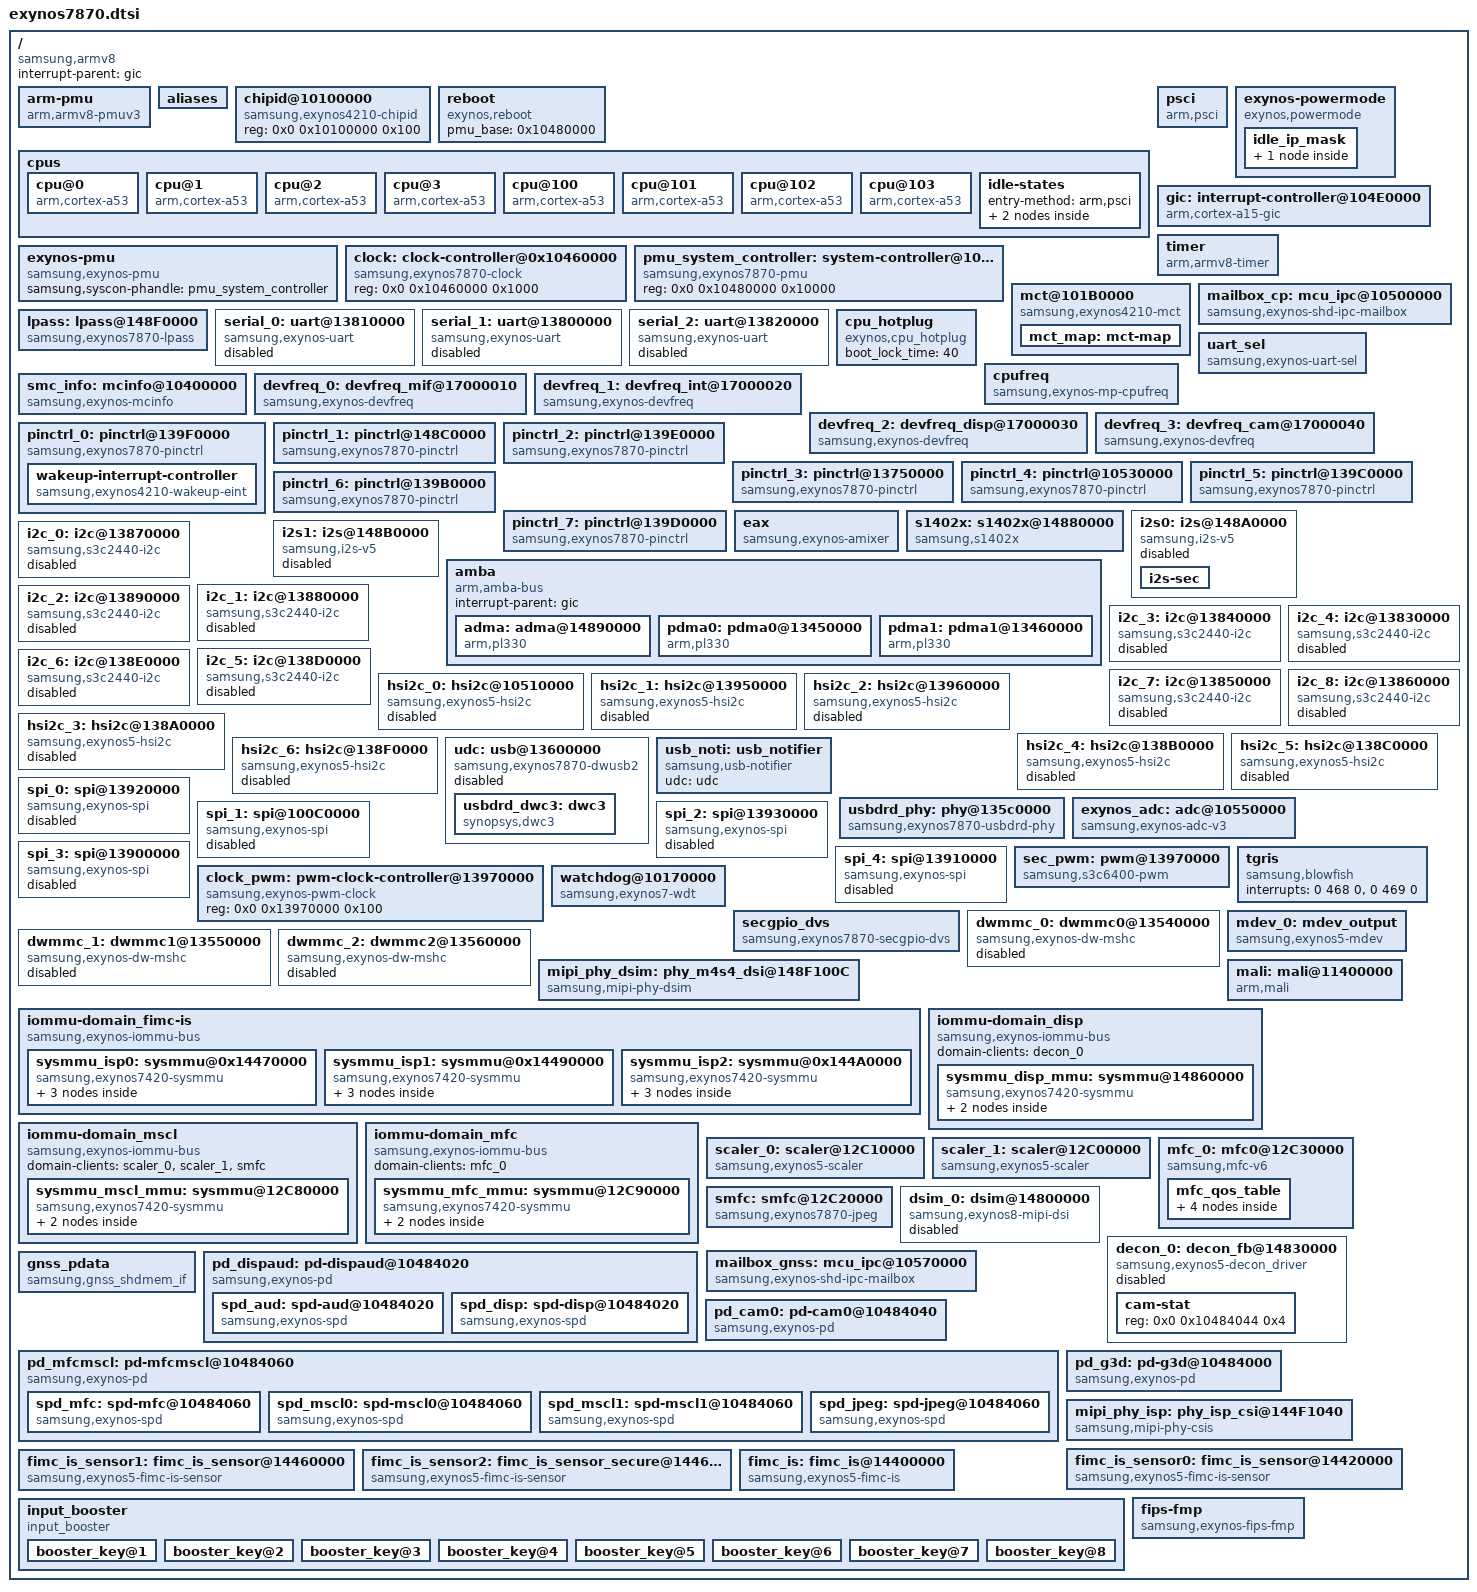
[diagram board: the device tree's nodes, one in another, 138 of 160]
/*
 * SAMSUNG EXYNOS7870 SoC device tree source
 *
 * Copyright (c) 2015 Samsung Electronics Co., Ltd.
 *		http://www.samsung.com
 *
 * SAMSUNG EXYNOS7870 SoC device nodes are listed in this file.
 * EXYNOS7870 based board files can include this file and provide
 * values for board specfic bindings.
 *
 * This program is free software; you can redistribute it and/or modify
 * it under the terms of the GNU General Public License version 2 as
 * published by the Free Software Foundation.
 */


#include <dt-bindings/clock/exynos7870.h>
#include <dt-bindings/sysmmu/sysmmu.h>
#include <dt-bindings/thermal/thermal.h>

#include "exynos7870-pinctrl.dtsi"
#include "exynos7870-busmon.dtsi"

/ {
	compatible = "samsung,armv8", "samsung,exynos7870";
	interrupt-parent = <&gic>;
	#address-cells = <2>;
	#size-cells = <1>;

	arm-pmu {
		compatible = "arm,armv8-pmuv3";
		interrupts = <0 34 4>,
			     <0 35 4>,
			     <0 36 4>,
			     <0 37 4>,
			     <0 50 4>,
			     <0 51 4>,
			     <0 52 4>,
			     <0 53 4>;
	};

	aliases {
		pinctrl0 = &pinctrl_0;
		pinctrl1 = &pinctrl_1;
		pinctrl2 = &pinctrl_2;
		pinctrl3 = &pinctrl_3;
		pinctrl4 = &pinctrl_4;
		pinctrl5 = &pinctrl_5;
		pinctrl6 = &pinctrl_6;
		pinctrl7 = &pinctrl_7;
		uart0 = &serial_0;
		uart1 = &serial_1;
		uart2 = &serial_2;
		hsi2c0 = &hsi2c_0;
		hsi2c1 = &hsi2c_1;
		hsi2c2 = &hsi2c_2;
		hsi2c3 = &hsi2c_3;
		hsi2c4 = &hsi2c_4;
		hsi2c5 = &hsi2c_5;
		hsi2c6 = &hsi2c_6;
		spi0 = &spi_0;
		spi1 = &spi_1;
		spi2 = &spi_2;
		spi3 = &spi_3;
		spi4 = &spi_4;
		mshc0 = &dwmmc_0;
//+++ MRVL_LOCAL
		mshc1 = &dwmmc_1;
//--- MRVL_LOCAL
		mshc2 = &dwmmc_2;
		decon0 = &decon_0;
		dsim0 = &dsim_0;
		scaler0 = &scaler_0;
		scaler1 = &scaler_1;
		mfc0 = &mfc_0;
		tmuctrl0 = &tmuctrl_0;
		tmuctrl1 = &tmuctrl_1;
		tmuctrl2 = &tmuctrl_2;
		ni2c0 = &i2c_0;
		ni2c1 = &i2c_1;
		ni2c2 = &i2c_2;
		ni2c3 = &i2c_3;
		ni2c4 = &i2c_4;
		ni2c5 = &i2c_5;
		ni2c6 = &i2c_6;
		ni2c7 = &i2c_7;
		ni2c8 = &i2c_8;
	};

	chipid@10100000 {
		compatible = "samsung,exynos4210-chipid";
		reg = <0x0 0x10100000 0x100>;
	};

	reboot {
		compatible = "exynos,reboot";
		pmu_base = <0x10480000>;
	};

	cpus {
		#address-cells = <2>;
		#size-cells = <0>;

		cpu@0 {
			device_type = "cpu";
			compatible = "arm,cortex-a53", "arm,armv8";
			reg = <0x0 0x0>;
			enable-method = "psci";
			cpu-idle-states = <&CPU_SLEEP_BOOT>;
		};
		cpu@1 {
			device_type = "cpu";
			compatible = "arm,cortex-a53", "arm,armv8";
			reg = <0x0 0x1>;
			enable-method = "psci";
			cpu-idle-states = <&CPU_SLEEP_BOOT>;
		};
		cpu@2 {
			device_type = "cpu";
			compatible = "arm,cortex-a53", "arm,armv8";
			reg = <0x0 0x2>;
			enable-method = "psci";
			cpu-idle-states = <&CPU_SLEEP_BOOT>;
		};
		cpu@3 {
			device_type = "cpu";
			compatible = "arm,cortex-a53", "arm,armv8";
			reg = <0x0 0x3>;
			enable-method = "psci";
			cpu-idle-states = <&CPU_SLEEP_BOOT>;
		};
		cpu@100 {
			device_type = "cpu";
			compatible = "arm,cortex-a53", "arm,armv8";
			reg = <0x0 0x100>;
			enable-method = "psci";
			cpu-idle-states = <&CPU_SLEEP_NONBOOT>;
		};
		cpu@101 {
			device_type = "cpu";
			compatible = "arm,cortex-a53", "arm,armv8";
			reg = <0x0 0x101>;
			enable-method = "psci";
			cpu-idle-states = <&CPU_SLEEP_NONBOOT>;
		};
		cpu@102 {
			device_type = "cpu";
			compatible = "arm,cortex-a53", "arm,armv8";
			reg = <0x0 0x102>;
			enable-method = "psci";
			cpu-idle-states = <&CPU_SLEEP_NONBOOT>;
		};
		cpu@103 {
			device_type = "cpu";
			compatible = "arm,cortex-a53", "arm,armv8";
			reg = <0x0 0x103>;
			enable-method = "psci";
			cpu-idle-states = <&CPU_SLEEP_NONBOOT>;
		};
		idle-states {
			entry-method = "arm,psci";

			CPU_SLEEP_BOOT: cpu-sleep-boot {
				desc = "boot cluster cpu sleep";
				compatible = "exynos,idle-state";
				arm,psci-suspend-param = <0x0010000>;
				entry-latency-us = <35>;
				exit-latency-us = <90>;
				min-residency-us = <750>;
				status = "okay";
			};

			CPU_SLEEP_NONBOOT: cpu-sleep-nonboot {
				desc = "non-boot cluster cpu sleep";
				compatible = "exynos,idle-state";
				arm,psci-suspend-param = <0x0010000>;
				entry-latency-us = <35>;
				exit-latency-us = <90>;
				min-residency-us = <750>;
				status = "okay";
			};
		};
	};

	exynos-pmu {
		compatible = "samsung,exynos-pmu";
		samsung,syscon-phandle = <&pmu_system_controller>;
	};

	psci {
                compatible = "arm,psci";
                method = "smc";
                cpu_suspend = <0xC4000001>;
                cpu_off = <0x84000002>;
                cpu_on = <0xC4000003>;
        };

	exynos-powermode {
		compatible = "exynos,powermode";

		/*	        sicd		aftr	stop	lpd	sleep	*/
		wakeup_mask =  <0x40000000>,	<0x0>,	<0x0>,	<0x0>,	<0x50006E1E>;
		wakeup_mask2 = <0x0>,		<0x0>,	<0x0>,	<0x0>,	<0xFFFF00FF>;
		wakeup_mask3 = <0x0>,		<0x0>,	<0x0>,	<0x0>,	<0xFFFF00FF>;

		cpd_residency = <3000>;
		sicd_residency = <3000>;

		sicd_enabled = <1>;

		idle-ip = "13970000.pwm",		/* idle ip index : 0 */
			  "10550000.adc",		/* idle ip index : 1 */

			  "10510000.hsi2c",		/* idle ip index : 2 */
			  "13950000.hsi2c",		/* idle ip index : 3 */
			  "13960000.hsi2c",		/* idle ip index : 4 */
			  "138a0000.hsi2c",		/* idle ip index : 5 */
			  "138b0000.hsi2c",		/* idle ip index : 6 */
			  "138c0000.hsi2c",		/* idle ip index : 7 */
			  "138f0000.hsi2c",		/* idle ip index : 8 */

			  "13870000.i2c",		/* idle ip index : 9 */
			  "13880000.i2c",		/* idle ip index : 10 */
			  "13890000.i2c",		/* idle ip index : 11 */
			  "13840000.i2c",		/* idle ip index : 12 */
			  "13830000.i2c",		/* idle ip index : 13 */
			  "138d0000.i2c",		/* idle ip index : 14 */
			  "138e0000.i2c",		/* idle ip index : 15 */
			  "13850000.i2c",		/* idle ip index : 16 */
			  "13860000.i2c",		/* idle ip index : 17 */

			  "13540000.dwmmc0",		/* idle ip index : 18 */
			  "13550000.dwmmc1",		/* idle ip index : 19 */
			  "13560000.dwmmc2",		/* idle ip index : 20 */

			  "13600000.usb",		/* idle ip index : 21 */

			  "100c0000.spi",		/* idle ip index : 22 */
			  "13900000.spi",		/* idle ip index : 23 */
			  "13910000.spi",		/* idle ip index : 24 */
			  "13920000.spi",		/* idle ip index : 25 */
			  "13930000.spi",		/* idle ip index : 26 */

			  "10500000.mailbox-cp",	/* idle ip index : 27 */
			  "10570000.mailbox-gnss",	/* idle ip index : 28 */

			  "14830000.decon_fb",		/* idle ip index : 29 */
			  "pd-g3d",			/* idle ip index : 30 */
			  "pd-cam0",			/* idle ip index : 31 */
			  "pd-mfcmscl",			/* idle ip index : 32 */
			  "148f0000.lpass",             /* idle ip index : 33 */
			  "bluetooth";			/* idle ip index : 34 */
		idle_ip_mask {
			sicd: SYS_SICD {
				mode-index = <0>;
				ref-idle-ip = <0>,  <1>,  <2>,  <3>,  <4>,  <5>,  <6>,  <7>,  <8>,  <9>,
					     <10>, <11>, <12>, <13>, <14>, <15>, <16>, <17>, <18>, <19>,
					     <20>, <21>, <22>, <23>, <24>, <25>, <26>, <27>, <28>, <29>,
					     <30>, <31>, <32>, <33>, <34>;
			};
		};
	};

	gic:interrupt-controller@104E0000 {
		compatible = "arm,cortex-a15-gic", "arm,cortex-a9-gic";
		#interrupt-cells = <3>;
		#address-cells = <0>;
		interrupt-controller;
		reg =	<0x0 0x104E1000 0x1000>,
			<0x0 0x104E2000 0x1000>,
			<0x0 0x104E4000 0x2000>,
			<0x0 0x104E6000 0x2000>;
		interrupts = <1 9 0xf04>;
	};

	timer {
	        compatible = "arm,armv8-timer";
	        interrupts = <1 13 0xff01>,
	                     <1 14 0xff01>,
	                     <1 11 0xff01>,
	                     <1 10 0xff01>;
	        clock-frequency = <26000000>;
		use-clocksource-only;
	};

	clock: clock-controller@0x10460000 {
		compatible = "samsung,exynos7870-clock";
		reg = <0x0 0x10460000 0x1000>;
		#clock-cells = <1>;
	};

	pmu_system_controller: system-controller@10480000 {
		compatible = "samsung,exynos7870-pmu", "syscon";
		reg = <0x0 0x10480000 0x10000>;
	};

	mct@101B0000 {
		compatible = "samsung,exynos4210-mct";
		reg = <0x0 0x101B0000 0x800>;
		interrupt-controller;
		#interrupt-cells = <1>;
		interrupt-parent = <&mct_map>;
		interrupts =	<0>, <1>, <2>, <3>,
				<4>, <5>, <6>, <7>,
				<8>, <9>, <10>, <11>;
		clocks = <&clock 1>, <&clock 102>;
		clock-names = "fin_pll", "mct";
		use-clockevent-only;

		mct_map: mct-map {
			#interrupt-cells = <1>;
			#address-cells = <0>;
			#size-cells = <0>;
			interrupt-map = <0 &gic 0 102 0>,
					<1 &gic 0 103 0>,
					<2 &gic 0 104 0>,
					<3 &gic 0 105 0>,
					<4 &gic 0 106 0>,
					<5 &gic 0 107 0>,
					<6 &gic 0 108 0>,
					<7 &gic 0 109 0>,
					<8 &gic 0 110 0>,
					<9 &gic 0 111 0>,
					<10 &gic 0 112 0>,
					<11 &gic 0 113 0>;
		};
	};

	mailbox_cp: mcu_ipc@10500000 {
		compatible = "samsung,exynos7580-mailbox";

		reg = <0 0x10500000 0x17C>;
		interrupts = <0 369 0 >;

		mcu,id = <0>;
		mcu,name = "mcu_ipc";
		mcu,irq_affinity_mask = <3>;
	};

	lpass: lpass@148F0000 {
		compatible = "samsung,exynos7870-lpass";
		reg = <0x0 0x148F0000 0x1040>;
		clocks = <&clock 461>,		/* aud_pll */
			<&clock 413>,		/* dispaud_mi2s_aud */
			<&clock 462>,		/* d1_mi2s */
			<&clock 410>; 		/* dispaud_decon */

		clock-names = "fout_aud_pll", "dout_sclk_mi2s",
				"aclk_aud", "dispaud_decon";

		samsung,syscon-phandle = <&pmu_system_controller>;
		samsung,power-domain = <&spd_aud>;
		status = "okay";
	};

	/* UART_BTWIFIFM */
	serial_0: uart@13810000 {
		compatible = "samsung,exynos-uart";
		samsung,separate-uart-clk;
		reg = <0x0 0x13810000 0x100>;
		samsung,fifo-size = <256>;
		interrupts = <0 422 0>;
		pinctrl-names = "default";
		pinctrl-0 = <&uart0_bus>;
		clocks = <&clock 171>, <&clock 621>, <&clock 621>;
		clock-names = "gate_pclk0", "gate_uart0", "sclk_uart0";
		status = "disabled";
	};

	/* UART_SENSOR */
	serial_1: uart@13800000 {
		compatible = "samsung,exynos-uart";
		samsung,separate-uart-clk;
		reg = <0x0 0x13800000 0x100>;
		samsung,fifo-size = <16>;
		interrupts = <0 421 0>;
		pinctrl-names = "default";
		pinctrl-0 = <&uart1_bus>;
		clocks = <&clock 172>, <&clock 620>, <&clock 620>;
		clock-names = "gate_pclk1", "gate_uart1", "sclk_uart1";
		status = "disabled";
	};

	/* UART_DEBUG */
	serial_2: uart@13820000 {
		compatible = "samsung,exynos-uart";
		samsung,separate-uart-clk;
		reg = <0x0 0x13820000 0x100>;
		samsung,fifo-size = <256>;
		interrupts = <0 423 0>;
		pinctrl-names = "default", "uart_sleep";
		pinctrl-0 = <&uart2_bus>;
		pinctrl-1 = <&uart2_sleep>;
		clocks = <&clock 170>, <&clock 622>, <&clock 622>;
		clock-names = "gate_pclk2", "gate_uart2", "sclk_uart2";
		status = "disabled";
	};

	/* UART SWITCH FOR CP */
	uart_sel {
		compatible = "samsung,exynos-uart-sel";

		mbx_ap2cp_uart_noti = <30>;
		int_ap2cp_uart_noti = <15>;
	};

	cpu_hotplug {
		compatible = "exynos,cpu_hotplug";
		boot_lock_time = <40>;
	};

	cpufreq {
		compatible = "samsung,exynos-mp-cpufreq";

		/* For CPUFREQ table */
		/* CL0 */
		cl0_idx_num = <17>;
		cl0_max_support_idx = <2>;
		cl0_min_support_idx = <14>;
		cl0_boot_max_qos = <1482000>;
		cl0_boot_min_qos = <1482000>;
		cl0_boot_lock_time = <40000000>;
		cl0_en_ema = <1>;
		cl0_regulator = "BUCK1";

		/* CL1 */
		cl1_idx_num = <17>;
		cl1_max_support_idx = <2>;
		cl1_min_support_idx = <14>;
		cl1_boot_max_qos = <1482000>;
		cl1_boot_min_qos = <1482000>;
		cl1_boot_lock_time = <40000000>;
		cl1_en_ema = <1>;
		cl1_regulator = "BUCK1";
		cl1_en_smpl = <0>;

		/* CL0 table ->	 idx   freq    volt   bus_lock */
		cl0_dvfs_domain_name = "dvfs_cpucl0";
		cl0_dvfs_table = < 0  2002000  900000   933000
				   1  1924000  900000	933000
				   2  1794000  900000	933000
				   3  1690000  900000	933000
				   4  1586000  900000	933000
				   5  1482000  900000	933000
				   6  1352000  900000	933000
				   7  1248000  900000	933000
				   8  1144000  900000	933000
				   9  1014000  900000	933000
				  10   902000  900000	933000
				  11   839000  900000	933000
				  12   757000  800000	450000
				  13   676000  800000	450000
				  14   546000  800000	450000
				  15   449000  800000	450000
				  16   343000  800000	450000 >;

		/* CL1 table ->	 idx  freq    volt   bus_lock */
		cl1_dvfs_domain_name = "dvfs_cpucl1";
		cl1_dvfs_table = < 0  2002000  900000   933000
				   1  1924000  900000	933000
				   2  1794000  900000	933000
				   3  1690000  900000	933000
				   4  1586000  900000	933000
				   5  1482000  900000	933000
				   6  1352000  900000	933000
				   7  1248000  900000	933000
				   8  1144000  900000	933000
				   9  1014000  900000	933000
				  10   902000  900000	933000
				  11   839000  900000	933000
				  12   757000  800000	450000
				  13   676000  800000	450000
				  14   546000  800000	450000
				  15   449000  800000	450000
				  16   343000  800000	450000 >;
	};

	smc_info: mcinfo@10400000 {
		compatible = "samsung,exynos-mcinfo";
		reg = <0x0 0x104000F4 0x4>;
		/* start bit, width */
		bit_field = <0 3>;
		basecnt = <1>;
		irqcnt = <0>;
	};

	devfreq_0: devfreq_mif@17000010 {
		compatible = "samsung,exynos-devfreq";
		reg = <0x0 0x17000010 0x0>;
		clocks = <&clock 2000>, <&clock 2001>;
		clock-names = "dvfs_mif", "dvfs_mif_sw";
		devfreq_type = "mif";
		devfreq_domain_name = "dvfs_mif";
		opp_list_length = <7>;
		opp_list = < 0 902000 900000
			     1 825000 900000
			     2 728000 900000
			     3 676000 900000
			     4 546000 900000
			     5 451000 900000
			     6 275000 900000>;

		/* initial_freq, default_qos, suspend_freq, cal_qos_max, min_freq, max_freq */
		freq_info = <902000 451000 451000 902000 451000 902000>;

		/* PM QoS */
		boot_qos_timeout = <40>;

		use_get_dev = "false";
		polling_ms = <0>;

		/* governor data */
		gov_name = "simple_exynos";
		urgent_thres = <80>;
		upthreshold = <70>;
		downthreshold = <60>;
		idlethreshold = <50>;

		/* regulator */
		use_reg = "true";
		use_reg_dummy = "false";
		reg_name = "BUCK2";
		/* cold, cold_limit, min_cold, max_uV */
		volt_info = <25000 1250000 0 1300000>;

		use_tmu = "true";
		use_cl_dvfs = "false";
		use_sw_clk = "true";
	};

	devfreq_1: devfreq_int@17000020 {
		compatible = "samsung,exynos-devfreq";
		reg = <0x0 0x17000020 0x0>;
		clocks = <&clock 2002>;
		clock-names = "dvfs_int";
		devfreq_type = "int";
		devfreq_domain_name = "dvfs_int";
		opp_list_length = <4>;
		/* idx freq volt */
		opp_list = <0 400000 900000
			    1 334000 900000
			    2 200000 900000
			    3 134000 900000>;

		/* <initial_freq, default_qos, suspend_freq, cal_qos_max, min, max> */
		freq_info = <400000 134000 134000 400000 134000 400000>;

		/* PM QoS */
		boot_qos_timeout = <40>;

		/* default_dev_profile */
		use_get_dev = "false";
		polling_ms = <0>;

		/* governor data */
		gov_name = "simple_ondemand";
		upthreshold = <95>;
		downdifferential = <5>;
		multi_weight = <100>;

		/* regulator */
		use_reg = "true";
		use_reg_dummy = "false";
		reg_name = "BUCK2";
		/* <cold, cold_limit, min_cold, max_uV> */
		volt_info = <25000 1250000 0 1300000>;

		use_tmu = "true";
		use_cl_dvfs = "false";
		use_sw_clk = "false";
	};

	devfreq_2: devfreq_disp@17000030 {
		compatible = "samsung,exynos-devfreq";
		reg = <0x0 0x17000030 0x0>;
		clocks = <&clock 2004>;
		clock-names = "dvfs_disp";
		devfreq_type = "disp";
		devfreq_domain_name = "dvfs_disp";
		opp_list_length = <2>;
		/* idx freq volt */
		opp_list = <0 200000 900000
			    1 134000 900000>;

		/* <initial_freq, default_qos, suspend_freq, cal_qos_max, min, max> */
		freq_info = <200000 134000 134000 200000 134000 200000>;

		/* PM QoS */
		boot_qos_timeout = <40>;

		/* default dev profile */
		use_get_dev = "false";
		polling_ms = <0>;

		/* governor data */
		gov_name = "simple_ondemand";
		upthreshold = <95>;
		downdifferential = <5>;
		multi_weight = <100>;

		/* regulator */
		use_reg = "true";
		use_reg_dummy = "false";
		reg_name = "BUCK2";
		/* cold, cold_limit, min_cold, max_uV */
		volt_info = <25000 1250000 0 1300000>;

		use_tmu = "true";
		use_cl_dvfs = "false";
		use_sw_clk = "false";
	};

	devfreq_3: devfreq_cam@17000040 {
		compatible = "samsung,exynos-devfreq";
		reg = <0x0 0x17000040 0x0>;
		clocks = <&clock 2003>;
		clock-names = "dvfs_cam";
		devfreq_type = "cam";
		devfreq_domain_name = "dvfs_cam";
		opp_list_length = <2>;
		opp_list = <0 533000 900000
			    1 334000 900000
			    2 167000 900000>;

		/* <initial, default_qos, suspend_freq, cal_qos_max, min, max> */
		freq_info = <167000 167000 167000 533000 167000 533000>;

		/* PM QoS */
		boot_qos_timeout = <0>;

		/* default dev profile */
		use_get_dev = "false";
		polling_ms = <0>;

		/* governor data */
		gov_name = "simple_ondemand";
		upthreshold = <95>;
		downdifferential = <5>;
		multi_weight = <100>;

		/* regulator */
		use_reg = "true";
		use_reg_dummy = "true";
		reg_name = "BUCK2";
		/* cold, cold_limit, min_cold, max_uV */
		volt_info = <25000 1250000 0 1300000>;

		use_tmu = "true";
		use_cl_dvfs = "false";
		use_sw_clk = "false";
	};

	/* ALIVE */
	pinctrl_0: pinctrl@139F0000 {
		compatible = "samsung,exynos7870-pinctrl";
		reg = <0x0 0x139F0000 0x1000>;
		interrupts = <0 0 0>, <0 1 0>, <0 2 0>, <0 3 0>,
				<0 4 0>, <0 5 0>, <0 6 0>, <0 7 0>,
				<0 8 0>, <0 9 0>, <0 10 0>, <0 11 0>,
				<0 12 0>, <0 13 0>, <0 14 0>, <0 15 0>;
		wakeup-interrupt-controller {
			compatible = "samsung,exynos4210-wakeup-eint";
			interrupt-parent = <&gic>;
			interrupts = <0 16 0>;
		};
	};

	/* DISPAUD */
	pinctrl_1: pinctrl@148C0000 {
		compatible = "samsung,exynos7870-pinctrl";
		reg = <0x0 0x148C0000 0x1000>;
		interrupts = <0 68 0>;
	};

	/* ESE */
	pinctrl_2: pinctrl@139E0000 {
		compatible = "samsung,exynos7870-pinctrl";
		reg = <0x0 0x139E0000 0x1000>;
		interrupts = <0 441 0>;
	};

	/* FSYS */
	pinctrl_3: pinctrl@13750000 {
		compatible = "samsung,exynos7870-pinctrl";
		reg = <0x0 0x13750000 0x1000>;
		interrupts = <0 250 0>;
	};

	/* MIF */
	pinctrl_4: pinctrl@10530000 {
		compatible = "samsung,exynos7870-pinctrl";
		reg = <0x0 0x10530000 0x1000>;
		interrupts = <0 392 0>;
	};

	/* NFC */
	pinctrl_5: pinctrl@139C0000 {
		compatible = "samsung,exynos7870-pinctrl";
		reg = <0x0 0x139C0000 0x1000>;
		interrupts = <0 439 0>;
	};

	/* TOP */
	pinctrl_6: pinctrl@139B0000 {
		compatible = "samsung,exynos7870-pinctrl";
		reg = <0x0 0x139B0000 0x1000>;
		interrupts = <0 438 0>;
	};

	/* TOUCH */
	pinctrl_7: pinctrl@139D0000 {
		compatible = "samsung,exynos7870-pinctrl";
		reg = <0x0 0x139D0000 0x1000>;
		interrupts = <0 440 0>;
	};

	eax: eax {
                     compatible = "samsung,exynos-amixer";
                     status = "ok";
        };

	s1402x: s1402x@14880000 {
		compatible = "samsung,s1402x";
		reg = <0x0 0x14880000 0x200>;
		clocks = <&clock 463>,	/* d1_mixer */
			<&clock 412>;	/* dispaud_mi2s_aud */

		clock-names = "audmixer_dout", "audmixer_aclk";

		reg-alive = <0x10480080 0 0>;
		samsung,lpass-subip;
		/*bt-fm-combo*/
		status = "okay";
	};

	i2s0: i2s@148A0000 {
		compatible = "samsung,i2s-v5";
		reg = <0x0 0x148A0000 0x100>;
		dmas = <&adma 0
			&adma 2>;
		dma-names = "tx", "rx";
		interrupts = <0 69 0>;
		clocks = <&clock 413>,	/* dispaud_mi2s_aud */
			<&clock 462>,	/* d1_i2s */
			<&clock 462>;	/* d1_i2s */
		clock-names = "iis", "i2s_opclk0", "i2s_opclk1";
		samsung,amixer = <4>;
		samsung,supports-rstclr;
		samsung,supports-secdai;
		samsung,supports-esa-dma;
		samsung,i2s-str;
		samsung,rx-sram = <0x03000000 0x2000>;
		samsung,lpass-subip;
		status = "disabled";
		i2s-sec {
			dmas = <&adma 1>;
			dma-names = "tx-sec";
			clocks = <&clock 413>,	/* dispaud_mi2s_aud */
				<&clock 462>,	/* d1_i2s */
				<&clock 462>;	/* d1_i2s */
			clock-names = "iis", "i2s_opclk0", "i2s_opclk1";
		};
	};

	i2s1: i2s@148B0000 {
		compatible = "samsung,i2s-v5";
		reg = <0x0 0x148B0000 0x100>;
		dmas = <&adma 3>;
		dma-names = "rx";
		interrupts = <0 71 0>;
		clocks = <&clock 414>, /* dispaud_mi2s_amp */
			<&clock 462>,	/* d1_i2s */
			<&clock 462>;	/* d1_i2s */
		clock-names = "iis", "i2s_opclk0", "i2s_opclk1";
		samsung,supports-rstclr;
		samsung,i2s-str;
		samsung,supports-i2s-amp;
		samsung,lpass-subip;
		status = "disabled";
	};

	amba {
		#address-cells = <2>;
		#size-cells = <1>;
		compatible = "arm,amba-bus";
		interrupt-parent = <&gic>;
		ranges;

		adma: adma@14890000 {
			compatible = "arm,pl330", "arm,primecell";
			reg = <0x0 0x14890000 0x1000>;
			interrupts = <0 73 0>;
			clocks = <&clock 414>;
			clock-names = "apb_pclk";
			#dma-cells = <1>;
			#dma-channels = <4>;
			#dma-requests = <16>;
			#dma-mcode-addr = <0x03002000>;
			arm,primecell-periphid = <0x341330>;
			samsung,reset-reg = < 0x148F1000>;
			samsung,reset-bit = <3>;
			samsung,reset-high;
		 };
	};

	/* I2C_IFPMIC */
	i2c_0: i2c@13870000 {
		compatible = "samsung,s3c2440-i2c";
		reg = <0x0 0x13870000 0x100>;
		interrupts = <0 428 0>;
		#address-cells = <1>;
		#size-cells = <0>;
		pinctrl-names = "default";
		pinctrl-0 = <&i2c0_bus>;
		clocks = <&clock 118>, <&clock 118>;
		clock-names = "rate_i2c", "gate_i2c";
		status = "disabled";
	};

	/* I2C_MUIC */
	i2c_1: i2c@13880000 {
		compatible = "samsung,s3c2440-i2c";
		reg = <0x0 0x13880000 0x100>;
		interrupts = <0 429 0>;
		#address-cells = <1>;
		#size-cells = <0>;
		pinctrl-names = "default";
		pinctrl-0 = <&i2c1_bus>;
		clocks = <&clock 117>, <&clock 117>;
		clock-names = "rate_i2c", "gate_i2c";
		status = "disabled";
	};

	/* I2C_NFC */
	i2c_2: i2c@13890000 {
		compatible = "samsung,s3c2440-i2c";
		reg = <0x0 0x13890000 0x100>;
		interrupts = <0 430 0>;
		#address-cells = <1>;
		#size-cells = <0>;
		pinctrl-names = "default";
		pinctrl-0 = <&i2c2_bus>;
		clocks = <&clock 116>, <&clock 116>;
		clock-names = "rate_i2c", "gate_i2c";
		status = "disabled";
	};

	/* I2C_TSP */
	i2c_3: i2c@13840000 {
		compatible = "samsung,s3c2440-i2c";
		reg = <0x0 0x13840000 0x100>;
		interrupts = <0 425 0>;
		#address-cells = <1>;
		#size-cells = <0>;
		pinctrl-names = "default";
		pinctrl-0 = <&i2c3_bus>;
		clocks = <&clock 112>, <&clock 112>;
		clock-names = "rate_i2c", "gate_i2c";
		status = "disabled";
	};

	/* I2C_FUELGAUGE */
	i2c_4: i2c@13830000 {
		compatible = "samsung,s3c2440-i2c";
		reg = <0x0 0x13830000 0x100>;
		interrupts = <0 424 0>;
		#address-cells = <1>;
		#size-cells = <0>;
		pinctrl-names = "default";
		pinctrl-0 = <&i2c4_bus>;
		clocks = <&clock 114>, <&clock 114>;
		clock-names = "rate_i2c", "gate_i2c";
		status = "disabled";
	};

	/* I2C_SENSOR1 */
	i2c_5: i2c@138D0000 {
		compatible = "samsung,s3c2440-i2c";
		reg = <0x0 0x138D0000 0x100>;
		interrupts = <0 453 0>;
		#address-cells = <1>;
		#size-cells = <0>;
		pinctrl-names = "default";
		pinctrl-0 = <&i2c5_bus>;
		clocks = <&clock 110>, <&clock 110>;
		clock-names = "rate_i2c", "gate_i2c";
		status = "disabled";
	};

	/* I2C_SENSOR2 */
	i2c_6: i2c@138E0000 {
		compatible = "samsung,s3c2440-i2c";
		reg = <0x0 0x138E0000 0x100>;
		interrupts = <0 454 0>;
		#address-cells = <1>;
		#size-cells = <0>;
		pinctrl-names = "default";
		pinctrl-0 = <&i2c6_bus>;
		clocks = <&clock 111>, <&clock 111>;
		clock-names = "rate_i2c", "gate_i2c";
		status = "disabled";
	};

	/* I2C_TOUCHKEY */
	i2c_7: i2c@13850000 {
		compatible = "samsung,s3c2440-i2c";
		reg = <0x0 0x13850000 0x100>;
		interrupts = <0 426 0>;
		#address-cells = <1>;
		#size-cells = <0>;
		pinctrl-names = "default";
		pinctrl-0 = <&i2c7_bus>;
		clocks = <&clock 113>, <&clock 113>;
		clock-names = "rate_i2c", "gate_i2c";
		status = "disabled";
	};

	/* I2C_SPKAMP */
	i2c_8: i2c@13860000 {
		compatible = "samsung,s3c2440-i2c";
		reg = <0x0 0x13860000 0x100>;
		interrupts = <0 427 0>;
		#address-cells = <1>;
		#size-cells = <0>;
		pinctrl-names = "default";
		pinctrl-0 = <&i2c8_bus>;
		clocks = <&clock 115>, <&clock 115>;
		clock-names = "rate_i2c", "gate_i2c";
		status = "disabled";
	};

	/* HSI2C_MIF_AP */
	hsi2c_0: hsi2c@10510000 {
		compatible = "samsung,exynos5-hsi2c";
		samsung,check-transdone-int;
		reg = <0x0 0x10510000 0x2000>, <0x0 0x10500180 0x100>;
		interrupts = <0 371 0>, <0 372 0>;
		#address-cells = <1>;
		#size-cells = <0>;
		pinctrl-names = "default";
		pinctrl-0 = <&hs_i2c0_bus>;
		clocks = <&clock 601>, <&clock 601>;
		clock-names = "rate_hsi2c", "gate_hsi2c";
		samsung,scl-clk-stretching;
		gpio_sda= <&gpm0 0 0x1>;
		gpio_scl= <&gpm0 1 0x1>;
		status = "disabled";
	};

	/* HSI2C_MAINCAM */
	hsi2c_1: hsi2c@13950000 {
		compatible = "samsung,exynos5-hsi2c";
		samsung,check-transdone-int;
		reg = <0x0 0x13950000 0x1000>;
		interrupts = <0 457 0>;
		#address-cells = <1>;
		#size-cells = <0>;
		pinctrl-names = "default";
		pinctrl-0 = <&hs_i2c1_bus>;
		clocks = <&clock 131>, <&clock 131>;
		clock-names = "rate_hsi2c", "gate_hsi2c";
		samsung,scl-clk-stretching;
		gpio_sda= <&gpf3 1 0x1>;
		gpio_scl= <&gpf3 0 0x1>;
		status = "disabled";
	};

	/* HSI2C_FRONTCAM */
	hsi2c_2: hsi2c@13960000 {
		compatible = "samsung,exynos5-hsi2c";
		samsung,check-transdone-int;
		reg = <0x0 0x13960000 0x1000>;
		interrupts = <0 458 0>;
		#address-cells = <1>;
		#size-cells = <0>;
		pinctrl-names = "default";
		pinctrl-0 = <&hs_i2c2_bus>;
		clocks = <&clock 130>, <&clock 130>;
		clock-names = "rate_hsi2c", "gate_hsi2c";
		samsung,scl-clk-stretching;
		gpio_sda= <&gpf3 3 0x1>;
		gpio_scl= <&gpf3 2 0x1>;
		status = "disabled";
	};

	/* HSI2C_REARSENSOR */
	hsi2c_3: hsi2c@138A0000 {
		compatible = "samsung,exynos5-hsi2c";
		samsung,check-transdone-int;
		reg = <0x0 0x138A0000 0x1000>;
		interrupts = <0 449 0>;
		#address-cells = <1>;
		#size-cells = <0>;
		pinctrl-names = "default";
		pinctrl-0 = <&hs_i2c3_bus>;
		clocks = <&clock 135>, <&clock 135>;
		clock-names = "rate_hsi2c", "gate_hsi2c";
		samsung,scl-clk-stretching;
		gpio_sda= <&gpf0 0 0x1>;
		gpio_scl= <&gpf0 1 0x1>;
		status = "disabled";
	};

	/* HSI2C_REARAF */
	hsi2c_4: hsi2c@138B0000 {
		compatible = "samsung,exynos5-hsi2c";
		samsung,check-transdone-int;
		reg = <0x0 0x138B0000 0x1000>;
		interrupts = <0 450 0>;
		#address-cells = <1>;
		#size-cells = <0>;
		pinctrl-names = "default";
		pinctrl-0 = <&hs_i2c4_bus>;
		clocks = <&clock 134>, <&clock 134>;
		clock-names = "rate_hsi2c", "gate_hsi2c";
		samsung,scl-clk-stretching;
		gpio_sda= <&gpf1 0 0x1>;
		gpio_scl= <&gpf1 1 0x1>;
		status = "disabled";
	};

	/* HSI2C_FRONTSENSOR */
	hsi2c_5: hsi2c@138C0000 {
		compatible = "samsung,exynos5-hsi2c";
		samsung,check-transdone-int;
		reg = <0x0 0x138C0000 0x1000>;
		interrupts = <0 451 0>;
		#address-cells = <1>;
		#size-cells = <0>;
		pinctrl-names = "default";
		pinctrl-0 = <&hs_i2c5_bus>;
		clocks = <&clock 133>, <&clock 133>;
		clock-names = "rate_hsi2c", "gate_hsi2c";
		samsung,scl-clk-stretching;
		gpio_sda= <&gpf0 2 0x1>;
		gpio_scl= <&gpf0 3 0x1>;
		status = "disabled";
	};

	/* HSI2C_DEPTHCAM */
	hsi2c_6: hsi2c@138F0000 {
		compatible = "samsung,exynos5-hsi2c";
		samsung,check-transdone-int;
		reg = <0x0 0x138F0000 0x1000>;
		interrupts = <0 456 0>;
		#address-cells = <1>;
		#size-cells = <0>;
		pinctrl-names = "default";
		pinctrl-0 = <&hs_i2c6_bus>;
		clocks = <&clock 132>, <&clock 132>;
		clock-names = "rate_hsi2c", "gate_hsi2c";
		samsung,scl-clk-stretching;
		gpio_sda= <&gpf2 0 0x1>;
		gpio_scl= <&gpf2 1 0x1>;
		status = "disabled";
	};

	/* DMA */
	amba {
		#address-cells = <2>;
		#size-cells = <1>;
		compatible = "arm,amba-bus";
		interrupt-parent = <&gic>;
		ranges;

		pdma0: pdma0@13450000 {
			compatible = "arm,pl330", "arm,primecell";
			reg = <0x0 0x13450000 0x1000>;
			interrupts = <0 228 0>;
			clocks = <&clock 332>;
			clock-names = "apb_pclk";
			#dma-cells = <1>;
			#dma-channels = <8>;
			#dma-requests = <32>;
		};

		pdma1: pdma1@13460000 {
			compatible = "arm,pl330", "arm,primecell";
			reg = <0x0 0x13460000 0x1000>;
			interrupts = <0 229 0>;
			clocks = <&clock 333>;
			clock-names = "apb_pclk";
			#dma-cells = <1>;
			#dma-channels = <4>;
			#dma-requests = <32>;
			#dma-secure-mode = <1>;
		};
	};

	udc: usb@13600000 {
		compatible = "samsung,exynos7870-dwusb2";
		clocks = <&clock 335>, <&clock 336>, <&clock 350>;
		clock-names = "usbdrd20", "phyumux", "usb_pll";
		reg = <0x0 0x13600000 0x10000>;
		#address-cells = <2>;
		#size-cells = <1>;
		ranges;
		status = "disabled";

		usbdrd_dwc3: dwc3 {
			compatible = "synopsys,dwc3";
			reg = <0x0 0x13600000 0x10000>;
			interrupts = <0 230 0>;
			enable_sprs_transfer;
			phys = <&usbdrd_phy 0>, <&usbdrd_phy 1>;
			phy-names = "usb2-phy", "usb3-phy";
		};
	};

	usb_noti: usb_notifier {
		compatible = "samsung,usb-notifier";
		udc = <&udc>;
	};

	usbdrd_phy: phy@135c0000 {
		compatible = "samsung,exynos7870-usbdrd-phy";
		reg = <0x0 0x135c0000 0x100>;
		clocks = <&clock 335>, <&clock 336>, <&clock 350>;
		clock-names = "usbdrd20", "phyumux", "usb_pll";
		samsung,pmu-syscon = <&pmu_system_controller>;
		is_not_vbus_pad;
		use_additional_tuning;
		#phy-cells = <1>;
		#address-cells = <2>;
		#size-cells = <1>;
		ranges;
	};

	exynos_adc: adc@10550000 {
		compatible = "samsung,exynos-adc-v3";
		reg = <0x0 0x10550000 0x1000>;
		interrupts = <0 395 0>;
		#io-channel-cells = <1>;
		io-channel-ranges;
		clocks = <&clock 600>;
		clock-names = "gate_adcif";
	};

	exynos-pmu {
		compatible = "samsung,exynos-pmu";
		samsung,syscon-phandle = <&pmu_system_controller>;
	};

	/* SPI_VOICEPROCESSOR */
	spi_0: spi@13920000 {
		compatible = "samsung,exynos-spi";
		reg = <0x0 0x13920000 0x100>;
		samsung,spi-fifosize = <256>;
		interrupts = <0 431 0>;
/*
		dma-mode;
		dmas = <&pdma0 25
			&pdma0 24>;
*/
		dma-names = "tx", "rx";
		swap-mode;
		#address-cells = <1>;
		#size-cells = <0>;
		clocks = <&clock 191>, <&clock 633>;
		clock-names = "spi", "spi_busclk0";
		pinctrl-names = "default";
		pinctrl-0 = <&spi0_bus>;
		status = "disabled";
	};

	/* SPI_ESE */
	spi_1: spi@100C0000 {
		compatible = "samsung,exynos-spi";
		reg = <0x0 0x100C0000 0x100>;
		samsung,spi-fifosize = <256>;
		interrupts = <0 434 0>;
/*
		dma-mode;
		dmas = <&pdma0 19
			&pdma0 18>;
*/
		dma-names = "tx", "rx";
		swap-mode;
		#address-cells = <1>;
		#size-cells = <0>;
		clocks = <&clock 192>, <&clock 632>;
		clock-names = "spi", "spi_busclk0";
		pinctrl-names = "default";
		pinctrl-0 = <&spi1_bus>;
		status = "disabled";
	};

	/* SPI_SENSORHUB */
	spi_2: spi@13930000 {
		compatible = "samsung,exynos-spi";
		reg = <0x0 0x13930000 0x100>;
		samsung,spi-fifosize = <256>;
		interrupts = <0 455 0>;
/*
		dma-mode;
		dmas = <&pdma0 27
			&pdma0 26>;
*/
		dma-names = "tx", "rx";
		#address-cells = <1>;
		#size-cells = <0>;
		clocks = <&clock 190>, <&clock 634>;
		clock-names = "spi", "spi_busclk0";
		pinctrl-names = "default";
		pinctrl-0 = <&spi2_bus>;
		status = "disabled";
	};

	/* SPI_REARFROM */
	spi_3: spi@13900000 {
		compatible = "samsung,exynos-spi";
		reg = <0x0 0x13900000 0x100>;
		samsung,spi-fifosize = <256>;
		interrupts = <0 433 0>;
/*
		dma-mode;
		dmas = <&pdma0 23
			&pdma0 22>;
*/
		dma-names = "tx", "rx";
		swap-mode;
		#address-cells = <1>;
		#size-cells = <0>;
		clocks = <&clock 193>, <&clock 631>;
		clock-names = "spi", "spi_busclk0";
		pinctrl-names = "default";
		pinctrl-0 = <&spi3_bus>;
		status = "disabled";
	};

	/* SPI_FRONTFROM */
	spi_4: spi@13910000 {
		compatible = "samsung,exynos-spi";
		reg = <0x0 0x13910000 0x100>;
		samsung,spi-fifosize = <256>;
		interrupts = <0 432 0>;
/*
		dma-mode;
		dmas = <&pdma0 21
			&pdma0 20>;
*/
		dma-names = "tx", "rx";
		swap-mode;
		#address-cells = <1>;
		#size-cells = <0>;
		clocks = <&clock 194>, <&clock 630>;
		clock-names = "spi", "spi_busclk0";
		pinctrl-names = "default";
		pinctrl-0 = <&spi4_bus>;
		status = "disabled";
	};

	sec_pwm: pwm@13970000 {
		compatible = "samsung,s3c6400-pwm";
		reg = <0x0 0x13970000 0x100>;
		samsung,pwm-outputs = <0>, <1>, <2>, <3>, <4>;
		samsung,pwm-sclk-ctrl;
		#pwm-cells = <3>;
		clocks = <&clock 100>, <&clock 101>,
		       <&clock_pwm 1>, <&clock_pwm 2>,
		       <&clock_pwm 5>, <&clock_pwm 6>,
		       <&clock_pwm 7>, <&clock_pwm 8>,
		       <&clock_pwm 10>, <&clock_pwm 11>,
		       <&clock_pwm 12>, <&clock_pwm 13>;
		clock-names = "gate_timers", "sclk_pwm",
			"pwm-scaler0", "pwm-scaler1",
			"pwm-tdiv0", "pwm-tdiv1",
			"pwm-tdiv2", "pwm-tdiv3",
			"pwm-tin0", "pwm-tin1",
			"pwm-tin2", "pwm-tin3";
		status = "okay";
	};

	clock_pwm: pwm-clock-controller@13970000 {
		compatible = "samsung,exynos-pwm-clock";
		reg = <0x0 0x13970000 0x100>;
		#clock-cells = <1>;
	};

	/* TEEgris */
	tgris {
		compatible = "samsung,blowfish";
		interrupts = <0 468 0>, <0 469 0>;
	};

	watchdog@10170000 {
		compatible = "samsung,exynos7-wdt";
		reg = <0x0 0x10170000 0x100>;
		interrupts = <0 100 0>;
		clocks = <&clock 160>, <&clock 160>;
		clock-names = "rate_watchdog", "gate_watchdog";
		timeout-sec = <30>;
		samsung,syscon-phandle = <&pmu_system_controller>;
	};

	secgpio_dvs {
		compatible = "samsung,exynos7870-secgpio-dvs";
		status = "okay";
	};

	dwmmc_0: dwmmc0@13540000 {
		compatible = "samsung,exynos-dw-mshc";
		reg = <0x0 0x13540000 0x2000>;
		interrupts = <0 245 0>;
		#address-cells = <1>;
		#size-cells = <0>;
		clocks = <&clock 310>, <&clock 313>, <&clock 602>;
		clock-names = "biu", "ciu", "ciu_gate";
		status = "disabled";
	 };

//+++ MRVL_LOCAL
	dwmmc_1: dwmmc1@13550000 {
		compatible = "samsung,exynos-dw-mshc";
		reg = <0x0 0x13550000 0x2000>;
		interrupts = <0 246 0>;
		#address-cells = <1>;
		#size-cells = <0>;
		clocks = <&clock 311>, <&clock 314>, <&clock 603>;
		clock-names = "biu", "ciu", "ciu_gate";
		status = "disabled";
	};
//--- MRVL_LOCAL

	dwmmc_2: dwmmc2@13560000 {
		compatible = "samsung,exynos-dw-mshc";
		reg = <0x0 0x13560000 0x2000>;
		interrupts = <0 247 0>;
		#address-cells = <1>;
		#size-cells = <0>;
		clocks = <&clock 312>, <&clock 315>, <&clock 604>;
		clock-names = "biu", "ciu", "ciu_gate";
		status = "disabled";
	 };
	mipi_phy_dsim: phy_m4s4_dsi@148F100C {
		compatible = "samsung,mipi-phy-dsim";
		reg = <0x0 0x148F100C 0x4>;
		samsung,pmu-syscon = <&pmu_system_controller>;
		isolation 	= <0x070C>;
		reset 		= <0 	 >;
		#phy-cells = <1>;
	};

	mdev_0: mdev_output {
	        compatible = "samsung,exynos5-mdev";
	};

	mali: mali@11400000 {
		compatible = "arm,mali";
		reg = <0x0 0x11400000 0x5000>;
		interrupts = <0 282 0>, <0 283 0>, <0 281 0>;
		interrupt-names = "JOB", "MMU", "GPU";
		samsung,power-domain = <&pd_g3d>;
	};

	iommu-domain_fimc-is {
		compatible = "samsung,exynos-iommu-bus";
		#address-cells = <2>;
		#size-cells = <1>;
		ranges;

		domain-clients = <&fimc_is>, <&fimc_is_sensor0>, <&fimc_is_sensor1>, <&fimc_is_sensor2>;

		sysmmu_isp0: sysmmu@0x14470000 {
			 compatible = "samsung,exynos7420-sysmmu";
			 reg = <0x0 0x14470000 0x1000>;
			 interrupts = <0 128 0>;
			 qos = <15>;
			 clocks = <&clock 500>;
			 clock-names = "aclk";
			 sysmmu,block-when-stop;
			 pb-info {
				pb@0 {
					master_axi_id_list =    <&fimc_is_sensor0 AW(4) AW(5) AW(8) AW(9) AW(12) AW(13)>,
								<&fimc_is_sensor1 AW(4) AW(5) AW(8) AW(9) AW(12) AW(13)>,
								<&fimc_is_sensor2 AW(4) AW(5) AW(8) AW(9) AW(12) AW(13)>;
				};
				pb@1 {
					 master_axi_id_list =   <&fimc_is_sensor0 AW(0) AW(1) AW(2) NAID NAID NAID>,
								<&fimc_is_sensor1 AW(0) AW(1) AW(2) NAID NAID NAID>,
								<&fimc_is_sensor2 AW(0) AW(1) AW(2) NAID NAID NAID>;
				};
			 };
		 };

		sysmmu_isp1: sysmmu@0x14490000 {
			 compatible = "samsung,exynos7420-sysmmu";
			 reg = <0x0 0x14490000 0x1000>;
			 interrupts = <0 131 0>;
			 qos = <15>;
			 clocks = <&clock 500>;
			 clock-names = "aclk";
			 sysmmu,block-when-stop;
			 pb-info {
				pb@0 {
					 master_axi_id_list = <&fimc_is AR(0) AW(0) AW(2)>;
				};
				pb@1 {
					 master_axi_id_list = <&fimc_is AW(1) AW(3) AW(5)>;
				};
			 };
		};

		sysmmu_isp2: sysmmu@0x144A0000 {
			 compatible = "samsung,exynos7420-sysmmu";
			 reg = <0x0 0x144A0000 0x1000>;
			 interrupts = <0 134 0>;
			 qos = <15>;
			 clocks = <&clock 500>;
			 clock-names = "aclk";
			 pb-info {
				pb@0 {
					 master_axi_id_list = <&fimc_is NAID NAID NAID>;
				};
				pb@1 {
					 master_axi_id_list = <&fimc_is NAID NAID NAID>;
				};
			 };
		 };
	};

	iommu-domain_disp {
		compatible = "samsung,exynos-iommu-bus";
		#address-cells = <2>;
		#size-cells = <1>;
		ranges;

		domain-clients = <&decon_0>;

		sysmmu_disp_mmu: sysmmu@14860000 {
			compatible = "samsung,exynos7420-sysmmu";
			reg = <0x0 0x14860000 0x1000>;
			interrupts = <0 193 0>;
			qos = <15>;
			clocks = <&clock 400>;
			clock-names = "aclk";

			pb-info {
				pb@0 {
					master_axi_id_list = <&decon_0 AR(0) AR(4) AR(1) AR(2)>;
				};
			};
		};
	};

	iommu-domain_mscl {
		compatible = "samsung,exynos-iommu-bus";
		#address-cells = <2>;
		#size-cells = <1>;
		ranges;

		domain-clients = <&scaler_0>, <&scaler_1>, <&smfc>;

		sysmmu_mscl_mmu: sysmmu@12C80000 {
			compatible = "samsung,exynos7420-sysmmu";
			reg = <0x0 0x12C80000 0x1000>;
			interrupts = <0 402 0>;
			clocks = <&clock 10>;
			clock-names = "aclk";

			pb-info {
				pb@0 {
					master_axi_id_list = <&scaler_0>, <&scaler_1>, <&smfc>;
				};
			};
		};
	};

	iommu-domain_mfc {
		compatible = "samsung,exynos-iommu-bus";
		#address-cells = <2>;
		#size-cells = <1>;
		ranges;

		domain-clients = <&mfc_0>;

		sysmmu_mfc_mmu: sysmmu@12C90000 {
			compatible = "samsung,exynos7420-sysmmu";
			reg = <0x0 0x12C90000 0x1000>;
			interrupts = <0 352 0>;
			clocks = <&clock 11>;
			clock-names = "aclk";
			pb-info {
				pb@0 {
					master_axi_id_list = <&mfc_0>;
				};
			};
		};
	};

	/* SCALER_BI */
	scaler_0: scaler@12C10000 {
		compatible = "samsung,exynos5-scaler";
		reg = <0x0 0x12C10000 0x1300>;
		#pb-id-cells = <0>;
		interrupts = <0 401 0>;
		clocks = <&clock 14>;
		clock-names = "gate";
		mscl,cfw = <1>;
		samsung,power-domain = <&spd_mscl0>;
	};

	/* SCALER_POLY */
	scaler_1: scaler@12C00000 {
		compatible = "samsung,exynos5-scaler";
		reg = <0x0 0x12C00000 0x1300>;
		#pb-id-cells = <0>;
		interrupts = <0 400 0>;
		clocks = <&clock 15>;
		clock-names = "gate";
		mscl,cfw = <1>;
		samsung,power-domain = <&spd_mscl1>;
	};

	mfc_0: mfc0@12C30000 {
		compatible = "samsung,mfc-v6";
		#pb-id-cells = <0>;
		reg = <0x0 0x12C30000 0x10000>;
		interrupts = <0 354 0>;
		clock-names = "aclk_mfc";
		clocks = <&clock 17>;
		samsung,power-domain = <&spd_mfc>;
		status = "ok";
		ip_ver = <15>;
		clock_rate = <400000000>;
		min_rate = <100000>;
		num_qos_steps = <4>;
		mfc_qos_table {
			mfc_qos_variant_0 {
				thrd_mb = <0>;
				freq_mfc = <0>;
				freq_int = <134000>;
				freq_mif = <451000>;
				freq_cpu = <0>;
				freq_kfc = <0>;
				has_enc_table = <0>;
			};
			mfc_qos_variant_1 {		/* Enc table */
				thrd_mb = <108000>;
				freq_mfc = <0>;
				freq_int = <334000>;
				freq_mif = <546000>;
				freq_cpu = <0>;
				freq_kfc = <0>;
				has_enc_table = <0>;
			};
			mfc_qos_variant_2 {
				thrd_mb = <108000>;
				freq_mfc = <0>;
				freq_int = <200000>;
				freq_mif = <546000>;
				freq_cpu = <0>;
				freq_kfc = <0>;
				has_enc_table = <1>;
			};
			mfc_qos_variant_3 {
				thrd_mb = <244800>;
				freq_mfc = <0>;
				freq_int = <400000>;
				freq_mif = <902000>;
				freq_cpu = <0>;
				freq_kfc = <0>;
				has_enc_table = <0>;
			};
		};
	};

	smfc: smfc@12C20000 {
		compatible = "samsung,exynos7870-jpeg";
		reg = <0x0 0x12C20000 0x10000>;
		interrupts = <0 404 0>;
		exynos-jpeg,cfw;
		#pb-id-cells = <0>;
		clocks = <&clock 16>;
		clock-names = "gate";
		samsung,power-domain = <&spd_jpeg>;
		smfc,int_qos_minlock = <400000>;
	};

	dsim_0: dsim@14800000 {
		compatible = "samsung,exynos8-mipi-dsi";
		reg = <0x0 0x14800000 0x100>;
		interrupts = <0 207 0>;
		samsung,power-domain = <&spd_disp>;
		status = "disabled";

		phys = <&mipi_phy_dsim 0>;
		phy-names = "dsim_dphy";

		/* TBD: power domain will be added later */

		clocks = <&clock 411>, /* dispaud_dsim0 */
			 <&clock 434>, /* dispaud_mipiphy_rxclkesc0 */
			 <&clock 433>; /* dispaud_mipiphy_txbyteclkhs */
		clock-names = "dsim_pclk", "dphy_escclk", "dphy_byteclk";

		/* number of data lanes in use */
		data_lane_cnt = <4>;
	};

	decon_0: decon_fb@14830000 {
		compatible = "samsung,exynos5-decon_driver";
		#address-cells = <2>;
		#size-cells = <1>;
		ranges;

		reg = <0x0 0x14830000 0x8000>;
		#pb-id-cells = <4>;
		status = "disabled";

		samsung,power-domain = <&spd_disp>;
		/* int_0: fifo_irq, int_1: vsync_irq, int_2: frame_done_irq, 3: te_irq */
		interrupts = <0 201 0>, <0 202 0>, <0 203 0>, <0 360 0>;

		clocks = <&clock 460>, /* disp_pll */
			 <&clock 410>, /* dispaud_decon */
			 <&clock 452>, /* decon_eclk */
			 <&clock 450>, /* decon_vclk */
			 <&clock 453>, /* decon_eclk_local */
			 <&clock 451>; /* decon_vclk_local */
		clock-names = "disp_pll", "decon_core",  "eclk_user",  "vclk_user",  "eclk_leaf",  "vclk_leaf";

		ip_ver = <4>;
		max_win = <3>;
		n_sink_pad = <3>;
		n_src_pad = <1>;
		default_win = <0>;
		trig_mode = <0>;	/* 0: hw trigger, 1: sw trigger */
		dsi_mode = <0>;		/* 0: single dsi, 1: dual dsi */
		pinctrl-names = "decon_te_on", "decon_te_off";
		pinctrl-0 = <&decon_te_on>;
		pinctrl-1 = <&decon_te_off>;

		cam-stat {
			/* ISP_STATUS register */
			reg = <0x0 0x10484044 0x4>;
		};
	};

	mailbox_gnss: mcu_ipc@10570000 {
		compatible = "samsung,exynos-shd-ipc-mailbox";
		reg = <0x0 0x10570000 0x180>;
		mcu,name = "mcu_ipc_gnss";
		mcu,id = <1>;
		interrupts = <0 373 0 >;
	};

	mailbox_cp: mcu_ipc@10500000 {
		compatible = "samsung,exynos-shd-ipc-mailbox";
		reg = <0x0 0x10500000 0x180>;
		mcu,name = "mcu_ipc_cp";
		mcu,id = <0>;
		interrupts = <0 369 0>;
	};

	gnss_pdata {
		compatible = "samsung,gnss_shdmem_if";
		shmem,name = "KEPLER";
		shmem,device_node_name = "gnss_ipc";
		status = "okay";
		/* ACTIVE WATCHDOG WAKEUP */
		interrupts = <0 19 0>, <0 478 0>, <0 477 0>;
		samsung,syscon-phandle = <&pmu_system_controller>;

		mbx,int_ap2gnss_bcmd = <0>;
		mbx,int_ap2gnss_req_fault_info = <1>;
		mbx,int_ap2gnss_ipc_msg = <2>;
		mbx,int_ap2gnss_ack_wake_set = <3>;
		mbx,int_ap2gnss_ack_wake_clr = <4>;

		mbx,irq_gnss2ap_bcmd = <0>;
		mbx,irq_gnss2ap_rsp_fault_info = <1>;
		mbx,irq_gnss2ap_ipc_msg = <2>;
		mbx,irq_gnss2ap_req_wake_clr = <4>;

		mbx,reg_bcmd_ctrl = <0>, <1>, <2>, <3>;
		mbx,reg_rx_ipc_msg = <4>;
		mbx,reg_tx_ipc_msg = <5>;
		mbx,reg_wake_lock = <6>;
		mbx,reg_rx_head = <10>;
		mbx,reg_rx_tail = <11>;
		mbx,reg_tx_head = <12>;
		mbx,reg_tx_tail = <13>;
		mbx,reg_fault_info = <22>, <23>, <24>, <25>, <26>, <27>, <28>, <29>,
							 <30>, <31>;

		shmem,ipc_offset = <0x200000>;
		shmem,ipc_size = <0x200000>;

		/* for step counter sensor controlled by GNSS
		pinctrl-names = "gnss_sensor";
		pinctrl-0 = <&gnss_sensor_i2c &gnss_sensor_irq>;
		*/
	};

	pd_dispaud: pd-dispaud@10484020 {
		compatible = "samsung,exynos-pd";
		reg = <0x0 0x10484020 0x20>;
		cal_id = <0xB1380000>;
		bts-status = "enabled";

		spd_aud: spd-aud@10484020 {
			compatible = "samsung,exynos-spd";
		};

		spd_disp: spd-disp@10484020 {
			compatible = "samsung,exynos-spd";
		};
	};

	pd_cam0: pd-cam0@10484040 {
		compatible = "samsung,exynos-pd";
		reg = <0x0 0x10484040 0x20>;
		cal_id = <0xB1380002>;
		bts-status = "enabled";
	};

	pd_mfcmscl: pd-mfcmscl@10484060 {
		compatible = "samsung,exynos-pd";
		reg = <0x0 0x10484060 0x20>;
		cal_id = <0xB1380003>;
		bts-status = "enabled";

		spd_mfc: spd-mfc@10484060 {
			compatible = "samsung,exynos-spd";
		};
		spd_mscl0: spd-mscl0@10484060 {
			compatible = "samsung,exynos-spd";
		};
		spd_mscl1: spd-mscl1@10484060 {
			compatible = "samsung,exynos-spd";
		};
		spd_jpeg: spd-jpeg@10484060 {
			compatible = "samsung,exynos-spd";
		};
	};

	pd_g3d: pd-g3d@10484000 {
		compatible = "samsung,exynos-pd";
		reg = <0x0 0x10484000 0x20>;
		cal_id = <0xB1380001>;
		bts-status = "enabled";
	};

	mipi_phy_isp: phy_isp_csi@144F1040 {
		compatible = "samsung,mipi-phy-csis";
		reg = <0x0 0x144F1040 0x4>; /* SYSREG address for reset */
		samsung,pmu-syscon = <&pmu_system_controller>;
		isolation 	= <0x070C 0x0714 0x0734>; /* PMU address offset */
		reset 		= <0      1      2>; /* reset bit */
		option 		= <256    3      256>; /* option bit */
		#phy-cells = <1>;
	};

	fimc_is_sensor0: fimc_is_sensor@14420000 {
		/* CSIS0 */
		compatible = "samsung,exynos5-fimc-is-sensor";
		#pb-id-cells = <6>;
		reg = <0x0 0x14420000 0x10000>, /* MIPI-CSI0 */
			<0x0 0x14410000 0x10000>; /* FIMC-BNS */
		interrupts = <0 144 0>, /* MIPI-CSI0 */
			<0 137 0>; /* FIMC-BNS */
		samsung,power-domain = <&pd_cam0>;

		phys = <&mipi_phy_isp 0>;
		phy-names = "csis_dphy";

		clock-names =
			"isp_sensor0_sclk",
			"isp_sensor1_sclk",
			"isp_sensor2_sclk";
		clocks = <&clock 640>,
				<&clock 641>,
				<&clock 642>;
	};

	fimc_is_sensor1: fimc_is_sensor@14460000 {
		/* CSIS1 */
		compatible = "samsung,exynos5-fimc-is-sensor";
		#pb-id-cells = <6>;
		reg = <0x0 0x14460000 0x10000>, /* MIPI-CSI1 */
			<0x0 0x14410000 0x10000>; /* FIMC-BNS */
		interrupts = <0 145 0>, /* MIPI-CSI1 */
			<0 137 0>; /* FIMC-BNS */
		samsung,power-domain = <&pd_cam0>;

		phys = <&mipi_phy_isp 1>;
		phy-names = "csis_dphy";

		clock-names =
			"isp_sensor0_sclk",
			"isp_sensor1_sclk",
			"isp_sensor2_sclk";
		clocks = <&clock 640>,
				<&clock 641>,
				<&clock 642>;
	};

	fimc_is_sensor2: fimc_is_sensor_secure@14460000 {
		/* CSIS1 */
		compatible = "samsung,exynos5-fimc-is-sensor";
		#pb-id-cells = <6>;
		reg = <0x0 0x14460000 0x10000>, /* MIPI-CSI1 */
			<0x0 0x14410000 0x10000>; /* FIMC-BNS */
		interrupts = <0 145 0>, /* MIPI-CSI1 */
			<0 137 0>; /* FIMC-BNS */
		samsung,power-domain = <&pd_cam0>;

		phys = <&mipi_phy_isp 2>;
		phy-names = "csis_dphy";

		clock-names =
			"isp_sensor0_sclk",
			"isp_sensor1_sclk",
			"isp_sensor2_sclk";
		clocks = <&clock 640>,
				<&clock 641>,
				<&clock 642>;
	};

	fimc_is: fimc_is@14400000 {
		compatible = "samsung,exynos5-fimc-is";
		#pb-id-cells = <3>;
		reg = <0x0 0x14400000 0x10000>, /* FIMC-ISP */
			<0x0 0x14430000 0x10000>, /* MC-Scaler */
			<0x0 0x14440000 0x10000>, /* FIMC-VRA0 */
			<0x0 0x14450000 0x10000>, /* FIMC-VRA1 */
			<0x0 0x14480000 0x10000>; /* FIMC-ISP(setB) */

		interrupts = <0 139 0>, /* FIMC-ISP0 */
				<0 140 0>, /* FIMC-ISP1 */
				<0 141 0>, /* FIMC-ISP2 */
				<0 142 0>, /* MC-SCALER */
				<0 146 0>, /* FIMC-VRA0 */
				<0 147 0>; /* FIMC-VRA1 */
		samsung,power-domain = <&pd_cam0>;

		clock-names =
			"oscclk",

			"gate_isp_sysmmu",
			"gate_isp_ppmu",
			"gate_isp_bts",
			"gate_isp_cam",
			"gate_isp_isp",
			"gate_isp_vra",
			"pxmxdx_isp_vra",
			"pxmxdx_isp_cam",
			"pxmxdx_isp_isp",

			"umux_isp_clkphy_isp_s_rxbyteclkhs0_s4_user",
			"umux_isp_clkphy_isp_s_rxbyteclkhs0_s4s_user",

			"isp_sensor0_sclk",
			"isp_sensor1_sclk",
			"isp_sensor2_sclk";
		clocks = <&clock 1>,

				<&clock 500>,
				<&clock 501>,
				<&clock 502>,
				<&clock 510>,
				<&clock 511>,
				<&clock 512>,
				<&clock 513>,
				<&clock 514>,
				<&clock 515>,

				<&clock 520>,
				<&clock 521>,

				<&clock 640>,
				<&clock 641>,
				<&clock 642>;

		status = "ok";
	};

	input_booster {
		status = "okay";
		compatible = "input_booster";
		#address-cells = <1>;
		#size-cells = <0>;

		booster_key@1 {
			input_booster,label = "KEY";
			input_booster,type = <0>;	/* BOOSTER_DEVICE_KEY */

			input_booster,levels = <1>;

			/* Frequency table */
			/* for level	:	1_Head */
			input_booster,cpu_freqs = <1248000>;
			input_booster,hmp_boost = <1>;
			input_booster,kfc_freqs = <1248000>;
			input_booster,mif_freqs = <0>;
			input_booster,int_freqs = <0>;

			/* Time table */
			input_booster,head_times = <500>;
			input_booster,tail_times = <500>;
			input_booster,phase_times = <0>;
		};
		booster_key@2 {
			input_booster,label = "TOUCHKEY";
			input_booster,type = <1>;	/* BOOSTER_DEVICE_TOUCHKEY */

			input_booster,levels = <1>;

			/* Frequency table */
			/* for level	:	1_Head */
			input_booster,cpu_freqs = <1248000>;
			input_booster,hmp_boost = <1>;
			input_booster,kfc_freqs = <1248000>;
			input_booster,mif_freqs = <0>;
			input_booster,int_freqs = <0>;

			/* Time table */
			input_booster,head_times = <0>;
			input_booster,tail_times = <200>;
			input_booster,phase_times = <0>;
		};
		booster_key@3 {
			input_booster,label = "TOUCH";
			input_booster,type = <2>;	/* BOOSTER_DEVICE_TOUCH */

			input_booster,levels = <1 2 3>;

			/* Frequency table */
			/* for level	:	1_Head, 2_Head, 2_Tail */
			input_booster,cpu_freqs = <1248000 1248000 1014000>;
			input_booster,hmp_boost = <1 1 0>;
			input_booster,kfc_freqs = <1248000 1248000 1014000>;
			input_booster,mif_freqs = <0 0 0>;
			input_booster,int_freqs = <0 0 0>;

			/* Time table */
			input_booster,head_times = <200 200 0>;
			input_booster,tail_times = <0 0 300>;
			input_booster,phase_times = <0 0 0>;
		};
		booster_key@4 { // Input Booster +
			input_booster,label = "MULTITOUCH";
			input_booster,type = <3>;	/* BOOSTER_DEVICE_MULTITOUCH */

			input_booster,levels = <1 2>;

			/* Frequency table */
			/* for level	:	1_Head 2_Tail*/
			input_booster,cpu_freqs = <1482000 1014000>;
			input_booster,hmp_boost = <1 1>;
			input_booster,kfc_freqs = <1482000 1014000>;
			input_booster,mif_freqs = <0 0>;
			input_booster,int_freqs = <0 0>;

			/* Time table */
			input_booster,head_times = <1000 0>;
			input_booster,tail_times = <0 500>;
			input_booster,phase_times = <0 0>;
		};
		booster_key@5 {
			input_booster,label = "KEYBOARD";
			input_booster,type = <4>;	/* BOOSTER_DEVICE_KEYBOARD */

			input_booster,levels = <1 2>;

			/* Frequency table */
			/* for level	:	1_Head 2_Tail*/
			input_booster,cpu_freqs = <1248000 1248000>;
			input_booster,hmp_boost = <1 1>;
			input_booster,kfc_freqs = <1248000 1248000>;
			input_booster,mif_freqs = <0 0>;
			input_booster,int_freqs = <0 0>;

			/* Time table */
			input_booster,head_times = <200 200>;
			input_booster,tail_times = <0 0>;
			input_booster,phase_times = <0 0>;
		};
		booster_key@6 {
			input_booster,label = "MOUSE";
			input_booster,type = <5>;	/* BOOSTER_DEVICE_MOUSE */

			input_booster,levels = <1 2>;

			/* Frequency table */
			/* for level	:	1_Head 2_Tail*/
			input_booster,cpu_freqs = <1248000 1014000>;
			input_booster,hmp_boost = <1 0>;
			input_booster,kfc_freqs = <1248000 1014000>;
			input_booster,mif_freqs = <0 0>;
			input_booster,int_freqs = <0 0>;

			/* Time table */
			input_booster,head_times = <200 0>;
			input_booster,tail_times = <0 500>;
			input_booster,phase_times = <0 0>;
		};
		booster_key@7 {
			input_booster,label = "MOUSE WHEEL";
			input_booster,type = <6>;	/* BOOSTER_DEVICE_MOUSE */

			input_booster,levels = <1 2>;

			/* Frequency table */
			/* for level	:	1_Head 2_Tail*/
			input_booster,cpu_freqs = <1248000 0>;
			input_booster,hmp_boost = <1 0>;
			input_booster,kfc_freqs = <1248000 0>;
			input_booster,mif_freqs = <0 0>;
			input_booster,int_freqs = <0 0>;

			/* Time table */
			input_booster,head_times = <200 0>;
			input_booster,tail_times = <0 0>;
			input_booster,phase_times = <0 0>;
		};
		booster_key@8 {
			input_booster,label = "PEN HOVER";
			input_booster,type = <7>;	/* BOOSTER_DEVICE_MOUSE */

			input_booster,levels = <1 2>;

			/* Frequency table */
			/* for level	:	1_Head 2_Tail*/
			input_booster,cpu_freqs = <1248000 1014000>;
			input_booster,hmp_boost = <1 0>;
			input_booster,kfc_freqs = <1248000 1014000>;
			input_booster,mif_freqs = <0 0>;
			input_booster,int_freqs = <0 0>;

			/* Time table */
			input_booster,head_times = <200 0>;
			input_booster,tail_times = <0 500>;
			input_booster,phase_times = <0 0>;
		}; // Input Booster -
		/* If you need to add new key type, add it this position */
	};

	fips-fmp {
		compatible = "samsung,exynos-fips-fmp";
	};
};
